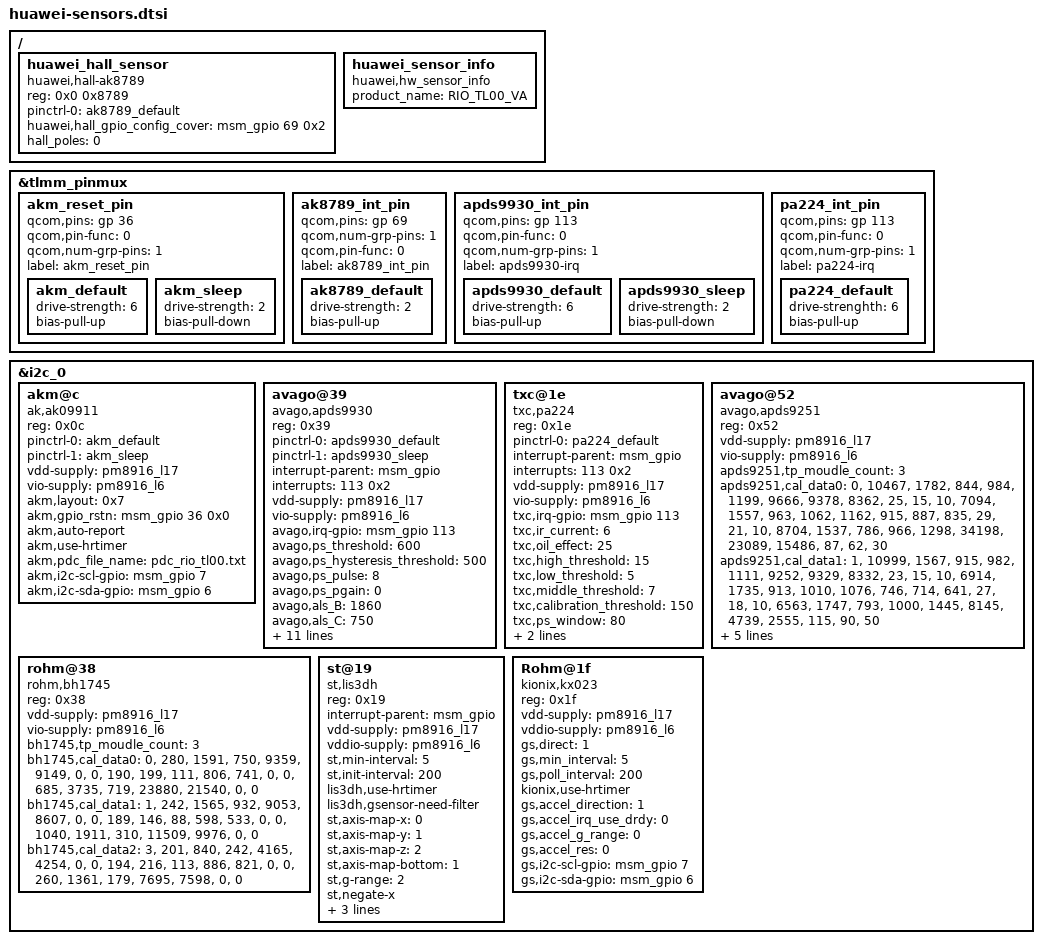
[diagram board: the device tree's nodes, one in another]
/* < DTS2014121804508 wangcunyou 20141218 begin */
/*use fromdos convert file format to linux*/
/* Copyright (c) 2013 The Linux Foundation. All rights reserved.
 *
 * This program is free software; you can redistribute it and/or modify
 * it under the terms of the GNU General Public License version 2 and
 * only version 2 as published by the Free Software Foundation.
 *
 * This program is distributed in the hope that it will be useful,
 * but WITHOUT ANY WARRANTY; without even the implied warranty of
 * MERCHANTABILITY or FITNESS FOR A PARTICULAR PURPOSE.  See the
 * GNU General Public License for more details.
 */
&tlmm_pinmux {
	akm_reset_pin {
		qcom,pins = <&gp 36>;
		qcom,pin-func = <0>;
		qcom,num-grp-pins = <1>;
		label = "akm_reset_pin";
		akm_default: akm_default {
			drive-strength = <6>;
			bias-pull-up;
		};
		akm_sleep: akm_sleep {
			drive-strength = <2>;
			bias-pull-down;
		};
	};
/* DTS2015012910874 dingjingfeng 20150206 begin> */
//delete lines
/* DTS2015012910874 dingjingfeng 20150206 end> */
	/* < DTS2014122304450 wangcunyou 20141223 begin */
	ak8789_int_pin {
		qcom,pins = <&gp 69>;
		qcom,num-grp-pins = <1>;
		qcom,pin-func = <0>;
		label = "ak8789_int_pin";
		ak8789_default: ak8789_default {
			  drive-strength = <2>;
			  bias-pull-up;
		};
	};
	/* DTS2014122304450 wangcunyou 20141223 end > */
	apds9930_int_pin {
		qcom,pins = <&gp 113>;
		qcom,pin-func = <0>;
		qcom,num-grp-pins = <1>;
		label = "apds9930-irq";
		apds9930_default: apds9930_default {
			drive-strength = <6>;
			bias-pull-up;
		};
		apds9930_sleep: apds9930_sleep {
			drive-strength = <2>;
			bias-pull-down;
		};
	};
	/* DTS2015031604601 wushengyu 20150316 begin> */
	pa224_int_pin {
		qcom,pins = <&gp 113>;
		qcom,pin-func = <0>;
		qcom,num-grp-pins = <1>;
		label = "pa224-irq";
		pa224_default: pa224_default {
			drive-strenghth = <6>;
			bias-pull-up;
		};
	};
	/* DTS2015031604601 wushengyu 20150316 end > */
};

&i2c_0 { /* BLSP1 QUP2 */
	akm@c {
		compatible = "ak,ak09911";
		reg = <0x0c>;
		pinctrl-names = "default","sleep";
		pinctrl-0 = <&akm_default>;
		pinctrl-1 = <&akm_sleep>;
		vdd-supply = <&pm8916_l17>;
		vio-supply = <&pm8916_l6>;
		akm,layout = <0x7>;
		akm,gpio_rstn = <&msm_gpio 36 0x0>;
		akm,auto-report;
		/* < DTS2015052009130 hufeng 20150601 begin */
		akm,use-hrtimer;
		/*  DTS2015052009130 hufeng 20150601 end > */
		/* < DTS2015032800844 caowei 20150319 begin */
		akm,pdc_file_name = "pdc_rio_tl00.txt";
		akm,i2c-scl-gpio = <&msm_gpio 7 0x0>;
		akm,i2c-sda-gpio = <&msm_gpio 6 0x0>;
		/* DTS2015032800844 caowei 20150319 end > */
	};

	avago@39 {
		compatible = "avago,apds9930";
		reg = <0x39>;
		pinctrl-names = "default","sleep";
		pinctrl-0 = <&apds9930_default>;
		pinctrl-1 = <&apds9930_sleep>;
		interrupt-parent = <&msm_gpio>;
		interrupts = <113 0x2>;
		vdd-supply = <&pm8916_l17>;
		vio-supply = <&pm8916_l6>;
		avago,irq-gpio = <&msm_gpio 113 0x2>;
		avago,ps_threshold = <600>;
		avago,ps_hysteresis_threshold = <500>;
		avago,ps_pulse = <8>;
		avago,ps_pgain = <0>;
		avago,als_B = <1860>;
		avago,als_C = <750>;
		avago,als_D = <1290>;
		avago,ga_value = <48>;
	        avago,ga_a_value = <112>;
		avago,ga_c_value = <450>;
		avago,ga_d_value = <162>;
		avago,window = <110>;
		avago,wave = <84>;
		avago,ga_e_value = <220>;
		avago,ga_f_value = <43>;
		/* < DTS2015032800844 caowei 20150319 begin */
		avago,i2c-scl-gpio = <&msm_gpio 7 0x0>;
		avago,i2c-sda-gpio = <&msm_gpio 6 0x0>;
		/* DTS2015032800844 caowei 20150319 end > */
	};
	/* DTS2015031604601 wushengyu 20150316 begin> */
	txc@1e {
		compatible = "txc,pa224";
		reg = <0x1e>;
		pinctrl-names = "default";
		pinctrl-0 = <&pa224_default>;
		interrupt-parent = <&msm_gpio>;
		interrupts = <113 0x2>;
		vdd-supply = <&pm8916_l17>;
		vio-supply = <&pm8916_l6>;
		txc,irq-gpio = <&msm_gpio 113 0x2>;
		/* < DTS2015051901259 wushengyu 20150528 begin */
		/*IR CURRENT 10MA*/
		txc,ir_current = <6>;
		/* < DTS2015062400454 wushengyu 20150624 begin */
		/* < DTS2015062703786 wushengyu 20150627 begin */
		txc,oil_effect = <25>;
		/* DTS2015062703786 wushengyu 20150627 end > */
		/* DTS2015062400454 wushengyu 20150624 end > */
		txc,high_threshold = <15>;
		txc,low_threshold = <5>;
		txc,middle_threshold = <7>;
		txc,calibration_threshold = <150>;
		/* DTS2015051901259 wushengyu 20150528 end > */
		/* < DTS2015030605077   wushengyu 20150306 begin */
		txc,ps_window = <80>;
		txc,ps_wave = <40>;
		/* DTS2015030605077   wushengyu 20150306 end > */
		txc,ps_defalt_crosstalk = <50>;

	};
	/* < DTS2015082101986 wushengyu 20150821 begin */
	avago@52 {
		compatible = "avago,apds9251";
		reg = <0x52>;
		vdd-supply = <&pm8916_l17>;
		vio-supply = <&pm8916_l6>;
		apds9251,tp_moudle_count = <3>;
		/*[module_id] [CCT_M] [CCT_N] [H] [A] [D] [LUX_P] [LUX_Q] [LUX_R] [cofficient0] [cofficient1] [cofficient2]*/
		apds9251,cal_data0 = "0","10467","1782","844","984","1199","9666","9378","8362","25","15","10",
		/*[CCT_M] [CCT_N] [H] [A] [D] [LUX_P] [LUX_Q] [LUX_R] [cofficient0] [cofficient1] [cofficient2]*/
		"7094","1557","963","1062","1162","915","887","835","29","21","10",
		/*[CCT_M] [CCT_N] [H] [A] [D] [LUX_P] [LUX_Q] [LUX_R] [cofficient0] [cofficient1] [cofficient2]*/
		"8704","1537","786","966","1298","34198","23089","15486","87","62","30";
		/*[module_id] [CCT_M] [CCT_N] [H] [A] [D] [LUX_P] [LUX_Q] [LUX_R] [cofficient0] [cofficient1] [cofficient2]*/
		apds9251,cal_data1 = "1","10999","1567","915","982","1111","9252","9329","8332","23","15","10",
		/*[CCT_M] [CCT_N] [H] [A] [D] [LUX_P] [LUX_Q] [LUX_R] [cofficient0] [cofficient1] [cofficient2]*/
		"6914","1735","913","1010","1076","746","714","641","27","18","10",
		/*[CCT_M] [CCT_N] [H] [A] [D] [LUX_P] [LUX_Q] [LUX_R] [cofficient0] [cofficient1] [cofficient2]*/
		"6563","1747","793","1000","1445","8145","4739","2555","115","90","50";
		/* < DTS2015090904335 wushengyu 20150909 begin */
		/*[module_id] [CCT_M] [CCT_N] [H] [A] [D] [LUX_P] [LUX_Q] [LUX_R] [cofficient0] [cofficient1] [cofficient2]*/
		apds9251,cal_data2 = "3","8796","1738","882","993","1092","5047","4989","4511","21","14","5",
		/*[CCT_M] [CCT_N] [H] [A] [D] [LUX_P] [LUX_Q] [LUX_R] [cofficient0] [cofficient1] [cofficient2]*/
		"6491","1636","946","1054","1159","1043","1004","940","30","19","10",
		/*[CCT_M] [CCT_N] [H] [A] [D] [LUX_P] [LUX_Q] [LUX_R] [cofficient0] [cofficient1] [cofficient2]*/
		"11215","1620","798","1100","1100","7853","9975","8486","47","25","10";
		/* DTS2015090904335 wushengyu 20150909 end > */
	};
	/* DTS2015082101986 wushengyu 20150407 end > */
	rohm@38 {
		compatible = "rohm,bh1745";
		reg = <0x38>;
		vdd-supply = <&pm8916_l17>;
		vio-supply = <&pm8916_l6>;
		/* < DTS2015032703190 wushengyu 20150618 begin */
		/* < DTS2015040700192 wushengyu 20150407 begin */
		/* < DTS2015070907832 wushengyu 20150709 begin */
		/* < DTS2015072402768 wushengyu 20150724 begin */
		bh1745,tp_moudle_count = <3>;
		/*[module_id] [golden judge] r[0] r[1] g[0] g[1] b[0] b[1]*/
		bh1745,cal_data0 = "0","280","1591","750","9359","9149","0","0",
		/*[white judge] r[0] r[1] g[0] g[1] b[0] b[1]*/
		"190","199","111","806","741","0","0",
		/*[black judge] r[0] r[1] g[0] g[1] b[0] b[1]*/
		"685","3735","719","23880","21540","0","0";
		/* < DTS2015070604652 wushengyu 20150706 begin */
		/*[module_id] [golden judge] r[0] r[1] g[0] g[1] b[0] b[1]*/
		bh1745,cal_data1 = "1","242","1565","932","9053","8607","0","0",
		/* DTS2015070604652 wushengyu 20150706 end > */
		/*[white judge] r[0] r[1] g[0] g[1] b[0] b[1]*/
		"189","146","88","598","533","0","0",
		/*[black judge] r[0] r[1] g[0] g[1] b[0] b[1]*/
		"1040","1911","310","11509","9976","0","0";
		/* DTS2015040700192 wushengyu 20150407 end > */
		/* DTS2015032703190 wushengyu 20150618 end > */
		/* < DTS2015090904335 wushengyu 20150909 begin */
		/*[module_id] [golden judge] r[0] r[1] g[0] g[1] b[0] b[1]*/
		bh1745,cal_data2 = "3","201","840","242","4165","4254","0","0",
		/*[white judge] r[0] r[1] g[0] g[1] b[0] b[1]*/
		"194","216","113","886","821","0","0",
		/*[black judge] r[0] r[1] g[0] g[1] b[0] b[1]*/
		"260","1361","179","7695","7598","0","0";
		/* DTS2015070907832 wushengyu 20150709 end > */
		/* DTS2015072402768 wushengyu 20150724 end > */
		/* DTS2015090904335 wushengyu 20150909 end > */
	};

	st@19 {
		compatible = "st,lis3dh";
		reg = <0x19>;
/* DTS2015012910874 dingjingfeng 20150206 begin> */
//delete lines
/* DTS2015012910874 dingjingfeng 20150206 end> */
		interrupt-parent = <&msm_gpio>;
		vdd-supply = <&pm8916_l17>;
		vddio-supply = <&pm8916_l6>;
		st,min-interval = <5>;
		st,init-interval = <200>;
		/*  DTS2015052009130 hufeng 20150601 end > */
		lis3dh,use-hrtimer;
		/* < DTS2015071609865  wushengyu 20150818 begin */
		lis3dh,gsensor-need-filter;
		/* DTS2015071609865 wushengyu 20150818 end > */
		/* < DTS2015052009130 hufeng 20150601 begin */
		st,axis-map-x = <0>;
		st,axis-map-y = <1>;
		st,axis-map-z = <2>;
		/*1 is bottom and others means top*/
		st,axis-map-bottom=<1>;
		st,g-range = <2>;
/* DTS2015012910874 dingjingfeng 20150206 begin> */
//delete lines
/* DTS2015012910874 dingjingfeng 20150206 end> */
		st,negate-x;
		st,negate-y;
		/* < DTS2015032800844 caowei 20150319 begin */
		st,i2c-scl-gpio = <&msm_gpio 7 0x0>;
		st,i2c-sda-gpio = <&msm_gpio 6 0x0>;
		/* DTS2015032800844 caowei 20150319 end > */
	};
	Rohm@1f {
		compatible = "kionix,kx023";
		reg = <0x1f>;
		/* DTS2015031604601 wushengyu 20150316 end > */
/* DTS2015012910874 dingjingfeng 20150206 begin> */
//delete lines
/* DTS2015012910874 dingjingfeng 20150206 end> */
		vdd-supply = <&pm8916_l17>;
		vddio-supply = <&pm8916_l6>;
		/* < DTS2014042813729 yangzhonghua 20140428 begin */
/* DTS2015012910874 dingjingfeng 20150206 begin> */
//delete lines
/* DTS2015012910874 dingjingfeng 20150206 end> */
		/* DTS2014042813729  yangzhonghua 20140428 end > */
		/* < DTS2014102905500 chuguoliang 20141029 begin */
		/*1 is bottom and others means top*/
		gs,direct = <1>;
		/* DTS2014102905500 chuguoliang 20141029 end > */
		gs,min_interval = <5>;
		gs,poll_interval = <200>;
		/* < DTS2015052009130 hufeng 20150601 begin */
		kionix,use-hrtimer;
		/*  DTS2015052009130 hufeng 20150601 end > */
		gs,accel_direction = <1>;
		gs,accel_irq_use_drdy = <0>;
		gs,accel_g_range = <0>;
		gs,accel_res = <0>;
		/* < DTS2015032800844 caowei 20150319 begin */
		gs,i2c-scl-gpio = <&msm_gpio 7 0x0>;
		gs,i2c-sda-gpio = <&msm_gpio 6 0x0>;
		/* DTS2015032800844 caowei 20150319 end > */
	};
	/* DTS2015012910874 dingjingfeng 20150206 begin> */
	/* DTS2015021203856 dingjingfeng 20150212 begin> */
	/* < DTS2015050402897 dingjingfeng 20150504 begin */
	//drop the sar sensor
	/* DTS2015050402897 dingjingfeng 20150504 end > */
	/* DTS2015021203856 dingjingfeng 20150212 end> */
	/* DTS2015012910874 dingjingfeng 20150206 end> */
};
/{
	/* < DTS2014122304450 wangcunyou 20141223 begin */
	huawei_hall_sensor{
		compatible = "huawei,hall-ak8789";
		reg = <0x0 0x8789>;
		pinctrl-names = "default";
		pinctrl-0 = <&ak8789_default>;
		huawei,hall_gpio_config_cover = <&msm_gpio 69 0x2>;
		hall_poles = <0>;
		status = "ok";
	};
	/* DTS2014122304450 wangcunyou 20141223 end > */
};
/* DTS2014121804508 wangcunyou 20141218 end > */
/* < DTS2015020511013 wangcunyou 20150205 begin */
/* < DTS2015032604389 wushengyu 20150326 begin */
/* < DTS2015033106262 wushengyu 20150331 begin */
/{
	huawei_sensor_info {
		compatible = "huawei,hw_sensor_info";
		product_name = "RIO_TL00_VA";
	};
};
/* DTS2015033106262 wushengyu 20150331 end > */
/* DTS2015032604389 wushengyu 20150326 end > */
/* DTS2015020511013 wangcunyou 20150205 end > */
